# f28e12x_uart_regs register map
Vendor: Texas Instruments
Peripheral module from a debugger description file (folder C2000).
Address unit: 16 bits
Registers are 32-bit, read-only, no defined reset value unless marked. A register's access mark holds for its fields unless they carry their own. Offsets are as the file gives them; lines under a group give offsets from that group; [hi:lo] are bit positions; {n}, {i} and the like mark numbered series; 'fields as' and 'values as' point back to an identical list; <NAME> marks a mode.

## UART_REGS — UART Registers
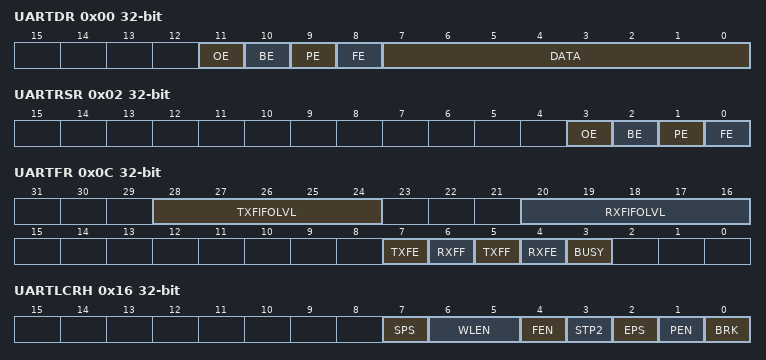
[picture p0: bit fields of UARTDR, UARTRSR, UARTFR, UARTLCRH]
0x00 UARTDR access per field — UART Data
  [11] OE ro — UART Overrun Error
  [10] BE ro — UART Break Error
  [9] PE ro — UART Parity Error
  [8] FE ro — UART Framing Error
  [7:0] DATA rw — Data Transmitted or Received
0x02 UARTRSR — UART Receive Status/Error Clear
  [3] OE — UART Overrun Error
  [2] BE — UART Break Error
  [1] PE — UART Parity Error
  [0] FE — UART Framing Error
0x0C UARTFR — UART Flag
  [28:24] TXFIFOLVL — UART Transmit FIFO Level
  [20:16] RXFIFOLVL — UART Receive FIFO Level
  [7] TXFE — UART Transmit FIFO Empty
  [6] RXFF — UART Receive FIFO Full
  [5] TXFF — UART Transmit FIFO Full
  [4] RXFE — UART Receive FIFO Empty
  [3] BUSY — UART Busy
0x10 UARTILPR rw — UART IrDA Low-Power Register
  [7:0] ILPDVSR — IrDA Low-Power Divisor
0x12 UARTIBRD rw — UART Integer Baud-Rate Divisor
  [15:0] DIVINT — Integer Baud-Rate Divisor
0x14 UARTFBRD rw — UART Fractional Baud-Rate Divisor
  [5:0] DIVFRAC — Fractional Baud-Rate Divisor
0x16 UARTLCRH rw — UART Line Control
  [7] SPS — UART Stick Parity Select
  [6:5] WLEN — UART Word Length
  [4] FEN — UART Enable FIFOs
  [3] STP2 — UART Two Stop Bits Select
  [2] EPS — UART Even Parity Select
  [1] PEN — UART Parity Enable
  [0] BRK — UART Send Break
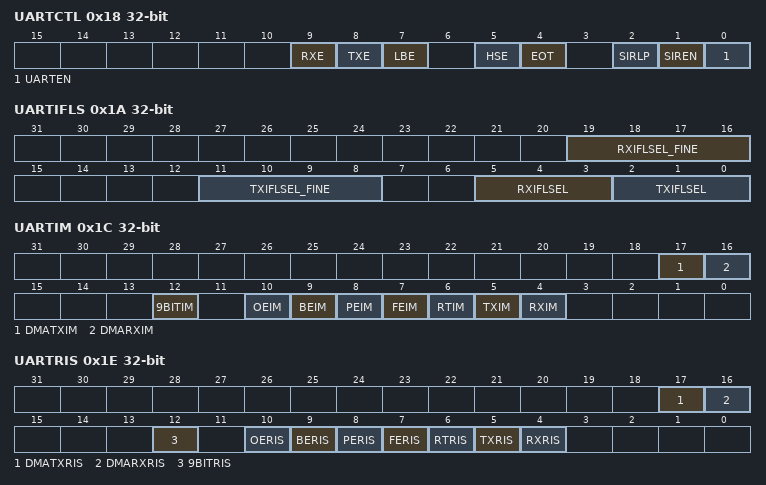
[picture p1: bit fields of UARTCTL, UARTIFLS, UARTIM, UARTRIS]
0x18 UARTCTL rw — UART Control
  [9] RXE — UART Receive Enable
  [8] TXE — UART Transmit Enable
  [7] LBE — UART Loop Back Enable
  [5] HSE — High-Speed Enable
  [4] EOT — End of Transmission
  [2] SIRLP — UART SIR Low-Power Mode
  [1] SIREN — UART SIR Enable
  [0] UARTEN — UART Enable
0x1A UARTIFLS rw — UART Interrupt FIFO Level Select
  [19:16] RXIFLSEL_FINE — UART Receive Interrupt Fine-grained FIFO Level Select
  [11:8] TXIFLSEL_FINE — UART Transmit Interrupt Fine-grained FIFO Level Select
  [5:3] RXIFLSEL — UART Receive Interrupt FIFO Level Select
  [2:0] TXIFLSEL — UART Transmit Interrupt FIFO Level Select
0x1C UARTIM rw — UART Interrupt Mask
  [17] DMATXIM — Transmit DMA Interrupt Mask
  [16] DMARXIM — Receive DMA Interrupt Mask
  [12] 9BITIM — 9-Bit Mode Interrupt Mask
  [10] OEIM — UART Overrun Error Interrupt Mask
  [9] BEIM — UART Break Error Interrupt Mask
  [8] PEIM — UART Parity Error Interrupt Mask
  [7] FEIM — UART Framing Error Interrupt Mask
  [6] RTIM — UART Receive Time-Out Interrupt Mask
  [5] TXIM — UART Transmit Interrupt Mask
  [4] RXIM — UART Receive Interrupt Mask
0x1E UARTRIS — UART Raw Interrupt Status
  [17] DMATXRIS — Transmit DMA Raw Interrupt Status
  [16] DMARXRIS — Receive DMA Raw Interrupt Status
  [12] 9BITRIS — 9-Bit Mode Raw Interrupt Status
  [10] OERIS — UART Overrun Error Raw Interrupt Status
  [9] BERIS — UART Break Error Raw Interrupt Status
  [8] PERIS — UART Parity Error Raw Interrupt Status
  [7] FERIS — UART Framing Error Raw Interrupt Status
  [6] RTRIS — UART Receive Time-Out Raw Interrupt Status
  [5] TXRIS — UART Transmit Raw Interrupt Status
  [4] RXRIS — UART Receive Raw Interrupt Status
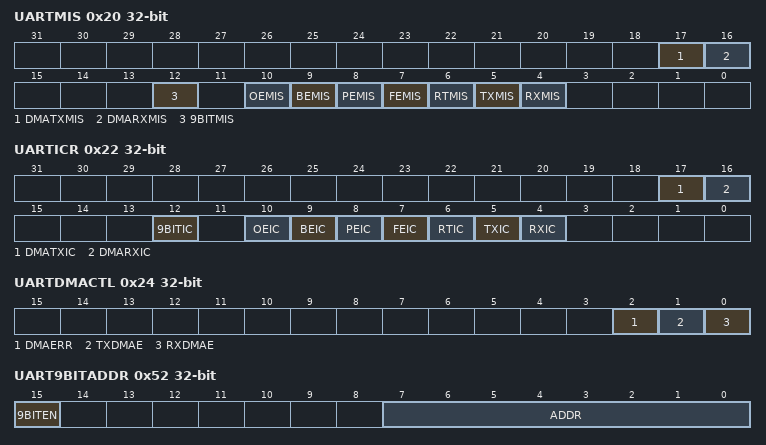
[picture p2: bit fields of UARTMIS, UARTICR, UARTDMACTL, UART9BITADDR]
0x20 UARTMIS — UART Masked Interrupt Status
  [17] DMATXMIS — Transmit DMA Masked Interrupt Status
  [16] DMARXMIS — Receive DMA Masked Interrupt Status
  [12] 9BITMIS — 9-Bit Mode Masked Interrupt Status
  [10] OEMIS — UART Overrun Error Masked Interrupt Status
  [9] BEMIS — UART Break Error Masked Interrupt Status
  [8] PEMIS — UART Parity Error Masked Interrupt Status
  [7] FEMIS — UART Framing Error Masked Interrupt Status
  [6] RTMIS — UART Receive Time-Out Masked Interrupt Status
  [5] TXMIS — UART Transmit Masked Interrupt Status
  [4] RXMIS — UART Receive Masked Interrupt Status
0x22 UARTICR rw — UART Interrupt Clear
  [17] DMATXIC — Transmit DMA Interrupt Clear
  [16] DMARXIC — Receive DMA Interrupt Clear
  [12] 9BITIC — 9-Bit Mode Interrupt Clear
  [10] OEIC — Overrun Error Interrupt Clear
  [9] BEIC — Break Error Interrupt Clear
  [8] PEIC — Parity Error Interrupt Clear
  [7] FEIC — Framing Error Interrupt Clear
  [6] RTIC — Receive Time-Out Interrupt Clear
  [5] TXIC — Transmit Interrupt Clear
  [4] RXIC — Receive Interrupt Clear
0x24 UARTDMACTL rw — UART DMA Control
  [2] DMAERR — DMA on Error
  [1] TXDMAE — Transmit DMA Enable
  [0] RXDMAE — Receive DMA Enable
0x40 UART_GLB_INT_EN access not given — UART Global Interrupt Enable Register
0x42 UART_GLB_INT_FLG — UART Global Interrupt Flag Register
  [0] INT_FLG — Global Interrupt Flag for UART Interrupt
0x44 UART_GLB_INT_CLR rw — UART Global Interrupt Clear Register
  [0] INT_FLG_CLR — Global Interrupt flag clear for UART Interrupt
0x52 UART9BITADDR rw — UART 9-Bit Self Address
  [15] 9BITEN — Enable 9-Bit Mode
  [7:0] ADDR — Self Address for 9-Bit Mode
0x54 UART9BITAMASK rw — UART 9-Bit Self Address Mask
  [7:0] MASK — Self Address Mask for 9-Bit Mode
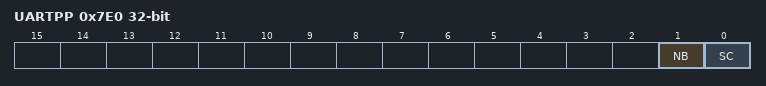
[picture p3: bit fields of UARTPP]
0x7E0 UARTPP — UART Peripheral Properties
  [1] NB — 9-Bit Support
  [0] SC — Smart Card Support
{0x7E0+2i} UARTPeriphID{i} (i=4..7) — UART Peripheral Identification {i}
  [7:0] PID{i} — UART Peripheral ID Register [{8i-25}:{8i-32}]
{0x7F0+2i} UARTPeriphID{i} (i=0..3) — UART Peripheral Identification {i}
  [7:0] PID{i} — UART Peripheral ID Register [{8i+7}:{8i}]
{0x7F8+2i} UARTPCellID{i} (i=0..3) — UART PrimeCell Identification {i}
  [7:0] CID{i} — UART PrimeCell ID Register [{8i+7}:{8i}]
